# MKL28T7_CORE1 register map
Vendor: Freescale Semiconductor, Inc.; Series: Kinetis_L; File version: 1.6
CPU: CM0PLUS r0p0, little endian, no MPU, no FPU, VTOR, 2 interrupt priority bits
Registers are 32-bit, read-write, reset 0x0 unless marked. A register's access mark holds for its fields unless they carry their own. Offsets are from the block's base; [hi:lo] are bit positions; {n}, {i} and the like mark numbered series; 'fields as' and 'values as' point back to an identical list.

## PCC1
Base 0x400FA000
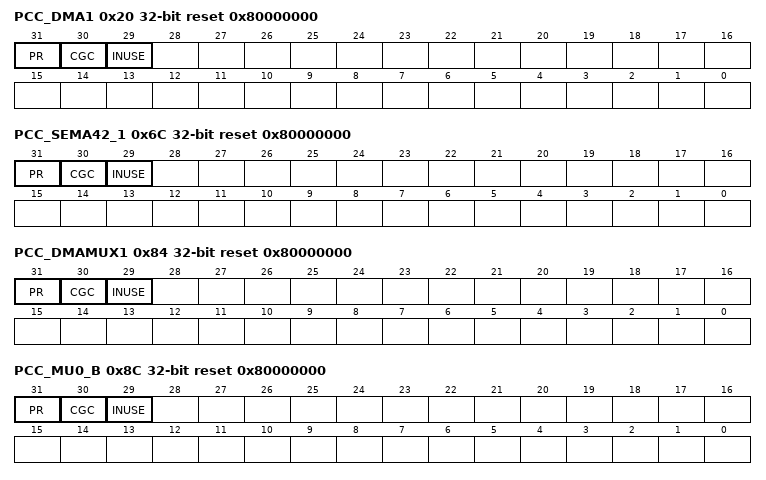
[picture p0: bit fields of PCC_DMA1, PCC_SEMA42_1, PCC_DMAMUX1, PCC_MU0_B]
0x20 PCC_DMA1 reset 0x80000000 — PCC CLKCFG Register
  [31] PR ro — Enable
    0=Peripheral is not present; 1=Peripheral is present
  [30] CGC — Clock Gate Control
    0=Clock disabled; 1=Clock enabled
  [29] INUSE ro — Clock Gate Control
    0=Another core is not using this peripheral; 1=Another core is using this peripheral. Software cannot modify the existing clocking configuration.
0x6C PCC_SEMA42_1 reset 0x80000000 — PCC CLKCFG Register
  fields as PCC_DMA1
0x84 PCC_DMAMUX1 reset 0x80000000 — PCC CLKCFG Register
  fields as PCC_DMA1
0x8C PCC_MU0_B reset 0x80000000 — PCC CLKCFG Register
  fields as PCC_DMA1
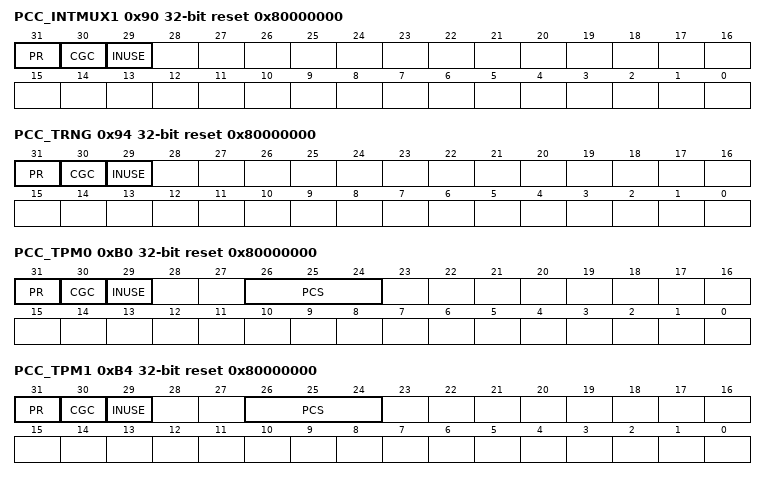
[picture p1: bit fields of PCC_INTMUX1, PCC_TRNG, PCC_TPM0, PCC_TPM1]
0x90 PCC_INTMUX1 reset 0x80000000 — PCC CLKCFG Register
  fields as PCC_DMA1
0x94 PCC_TRNG reset 0x80000000 — PCC CLKCFG Register
  fields as PCC_DMA1
0xB0 PCC_TPM0 reset 0x80000000 — PCC CLKCFG Register
  [31] PR ro — Enable
    0=Peripheral is not present; 1=Peripheral is present
  [30] CGC — Clock Gate Control
    0=Clock disabled; 1=Clock enabled
  [29] INUSE ro — Clock Gate Control
    values as PCC_DMA1.INUSE
  [26:24] PCS — Peripheral Clock Source Select
    0=Clock is off (or test clock is enabled); 1=OSCCLK - System Oscillator Bus Clock(scg_sosc_slow_clk); 2=SCGIRCLK - Slow IRC Clock(scg_sirc_slow_clk), (maximum is 8MHz); 3=SCGFIRCLK - Fast IRC Clock(scg_firc_slow_clk), (maximum is 48MHz); 6=SCGPCLK System PLL clock (scg_spll_slow_clk)
0xB4 PCC_TPM1 reset 0x80000000 — PCC CLKCFG Register
  fields as PCC_TPM0
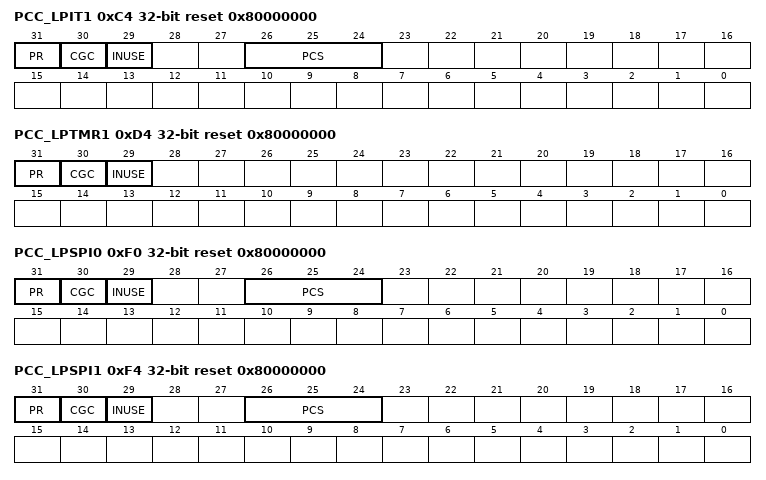
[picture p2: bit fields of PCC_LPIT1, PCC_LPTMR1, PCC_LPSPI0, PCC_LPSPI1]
0xC4 PCC_LPIT1 reset 0x80000000 — PCC CLKCFG Register
  fields as PCC_TPM0
0xD4 PCC_LPTMR1 reset 0x80000000 — PCC CLKCFG Register
  fields as PCC_DMA1
0xF0 PCC_LPSPI0 reset 0x80000000 — PCC CLKCFG Register
  fields as PCC_TPM0
0xF4 PCC_LPSPI1 reset 0x80000000 — PCC CLKCFG Register
  fields as PCC_TPM0
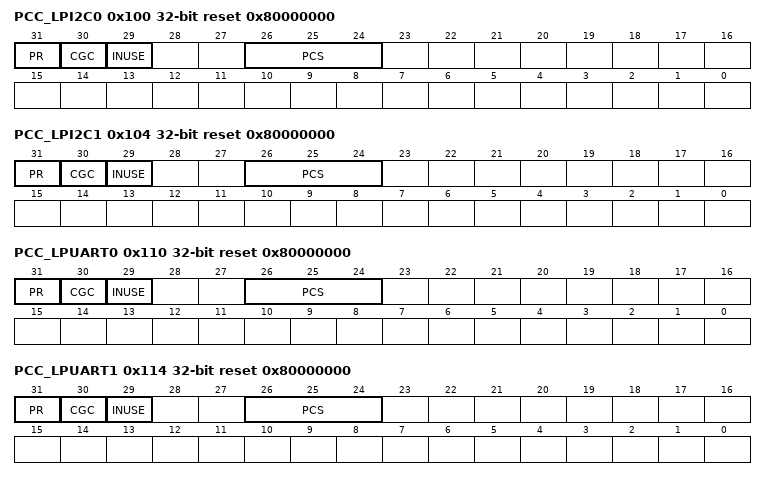
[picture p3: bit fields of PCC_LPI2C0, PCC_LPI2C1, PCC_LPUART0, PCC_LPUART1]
0x100 PCC_LPI2C0 reset 0x80000000 — PCC CLKCFG Register
  fields as PCC_TPM0
0x104 PCC_LPI2C1 reset 0x80000000 — PCC CLKCFG Register
  fields as PCC_TPM0
0x110 PCC_LPUART0 reset 0x80000000 — PCC CLKCFG Register
  fields as PCC_TPM0
0x114 PCC_LPUART1 reset 0x80000000 — PCC CLKCFG Register
  fields as PCC_TPM0
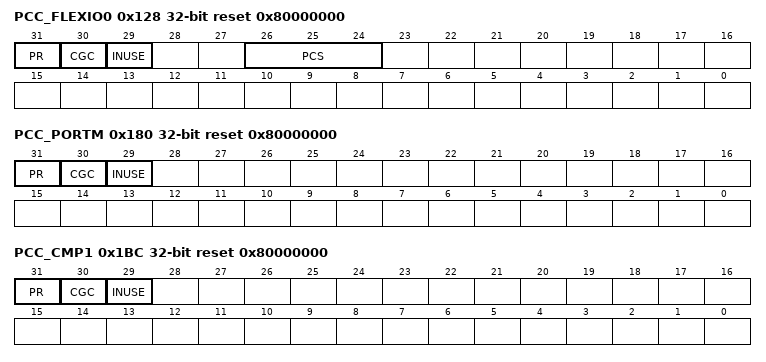
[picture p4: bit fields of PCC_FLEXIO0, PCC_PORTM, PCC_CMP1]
0x128 PCC_FLEXIO0 reset 0x80000000 — PCC CLKCFG Register
  fields as PCC_TPM0
0x180 PCC_PORTM reset 0x80000000 — PCC CLKCFG Register
  fields as PCC_DMA1
0x1BC PCC_CMP1 reset 0x80000000 — PCC CLKCFG Register
  fields as PCC_DMA1

## RFSYS — System register file
Base 0x4007C000; register names take the prefix RFSYS_
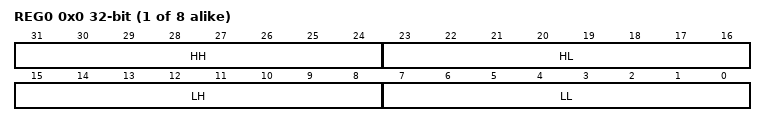
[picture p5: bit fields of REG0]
{0x0+4i} REG{i} (i=0..7) — Register file register
  [31:24] HH — High higher byte
  [23:16] HL — High lower byte
  [15:8] LH — Low higher byte
  [7:0] LL — Low lower byte

## PMC — Power Management Controller
Base 0x4007D000; register names take the prefix PMC_
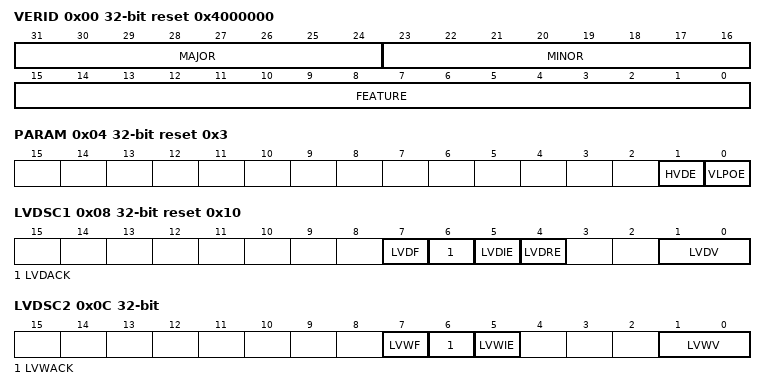
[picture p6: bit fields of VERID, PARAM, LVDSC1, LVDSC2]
0x00 VERID ro reset 0x4000000 — Version ID register
  [31:24] MAJOR — Major Version Number
  [23:16] MINOR — Minor Version Number
  [15:0] FEATURE — Feature Specification Number
    0=Standard features implemented
0x04 PARAM ro reset 0x3 — Parameter register
  [1] HVDE — HVD Enabled
  [0] VLPOE — VLPO Enable
0x08 LVDSC1 reset 0x10 — Low Voltage Detect Status And Control 1 register
  [7] LVDF ro — Low-Voltage Detect Flag
    0=Low-voltage event not detected; 1=Low-voltage event detected
  [6] LVDACK wo — Low-Voltage Detect Acknowledge
  [5] LVDIE — Low-Voltage Detect Interrupt Enable
    0=Hardware interrupt disabled (use polling); 1=Request a hardware interrupt when LVDF = 1
  [4] LVDRE — Low-Voltage Detect Reset Enable
    0=LVDF does not generate hardware resets; 1=Force an MCU reset when LVDF = 1
  [1:0] LVDV — Low-Voltage Detect Voltage Select
    0=Low trip point selected (V LVD = V LVDL ); 1=High trip point selected (V LVD = V LVDH )
0x0C LVDSC2 — Low Voltage Detect Status And Control 2 register
  [7] LVWF ro — Low-Voltage Warning Flag
    0=Low-voltage warning event not detected; 1=Low-voltage warning event detected
  [6] LVWACK wo — Low-Voltage Warning Acknowledge
  [5] LVWIE — Low-Voltage Warning Interrupt Enable
    0=Hardware interrupt disabled (use polling); 1=Request a hardware interrupt when LVWF = 1
  [1:0] LVWV — Low-Voltage Warning Voltage Select
    0=Low trip point selected (VLVW = VLVW1); 1=Mid 1 trip point selected (VLVW = VLVW2); 2=Mid 2 trip point selected (VLVW = VLVW3); 3=High trip point selected (VLVW = VLVW4)
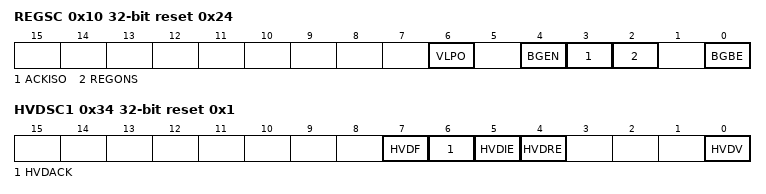
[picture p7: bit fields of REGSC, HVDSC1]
0x10 REGSC reset 0x24 — Regulator Status And Control register
  [6] VLPO — VLPx Option
    0=Operating frequencies and SCG clocking modes are restricted during VLPx modes as listed in the Power Management chapter; 1=If BGEN is also set, operating frequencies and SCG clocking modes are unrestricted during VLPx modes. Note that flash access frequency is still restricted however.
  [4] BGEN — Bandgap Enable In VLPx Operation
    0=Bandgap voltage reference is disabled in VLPx , LLS , and VLLSx modes; 1=Bandgap voltage reference is enabled in VLPx , LLS , and VLLSx modes
  [3] ACKISO — Acknowledge Isolation
    0=Peripherals and I/O pads are in normal run state; 1=Certain peripherals and I/O pads are in an isolated and latched state
  [2] REGONS ro — Regulator In Run Regulation Status
    0=Regulator is in stop regulation or in transition to/from it; 1=Regulator is in run regulation
  [0] BGBE — Bandgap Buffer Enable
    0=Bandgap buffer not enabled; 1=Bandgap buffer enabled
0x34 HVDSC1 reset 0x1 — High Voltage Detect Status And Control 1 register
  [7] HVDF ro — High-Voltage Detect Flag
    0=High-voltage event not detected; 1=High-voltage event detected
  [6] HVDACK wo — High-Voltage Detect Acknowledge
  [5] HVDIE — High-Voltage Detect Interrupt Enable
    0=Hardware interrupt disabled (use polling); 1=Request a hardware interrupt when HVDF = 1
  [4] HVDRE — High-Voltage Detect Reset Enable
    0=HVDF does not generate hardware resets; 1=Force an MCU reset when HVDF = 1
  [0] HVDV — High-Voltage Detect Voltage Select
    0=Low trip point selected (V HVD = V HVDL ); 1=High trip point selected (V HVD = V HVDH )
